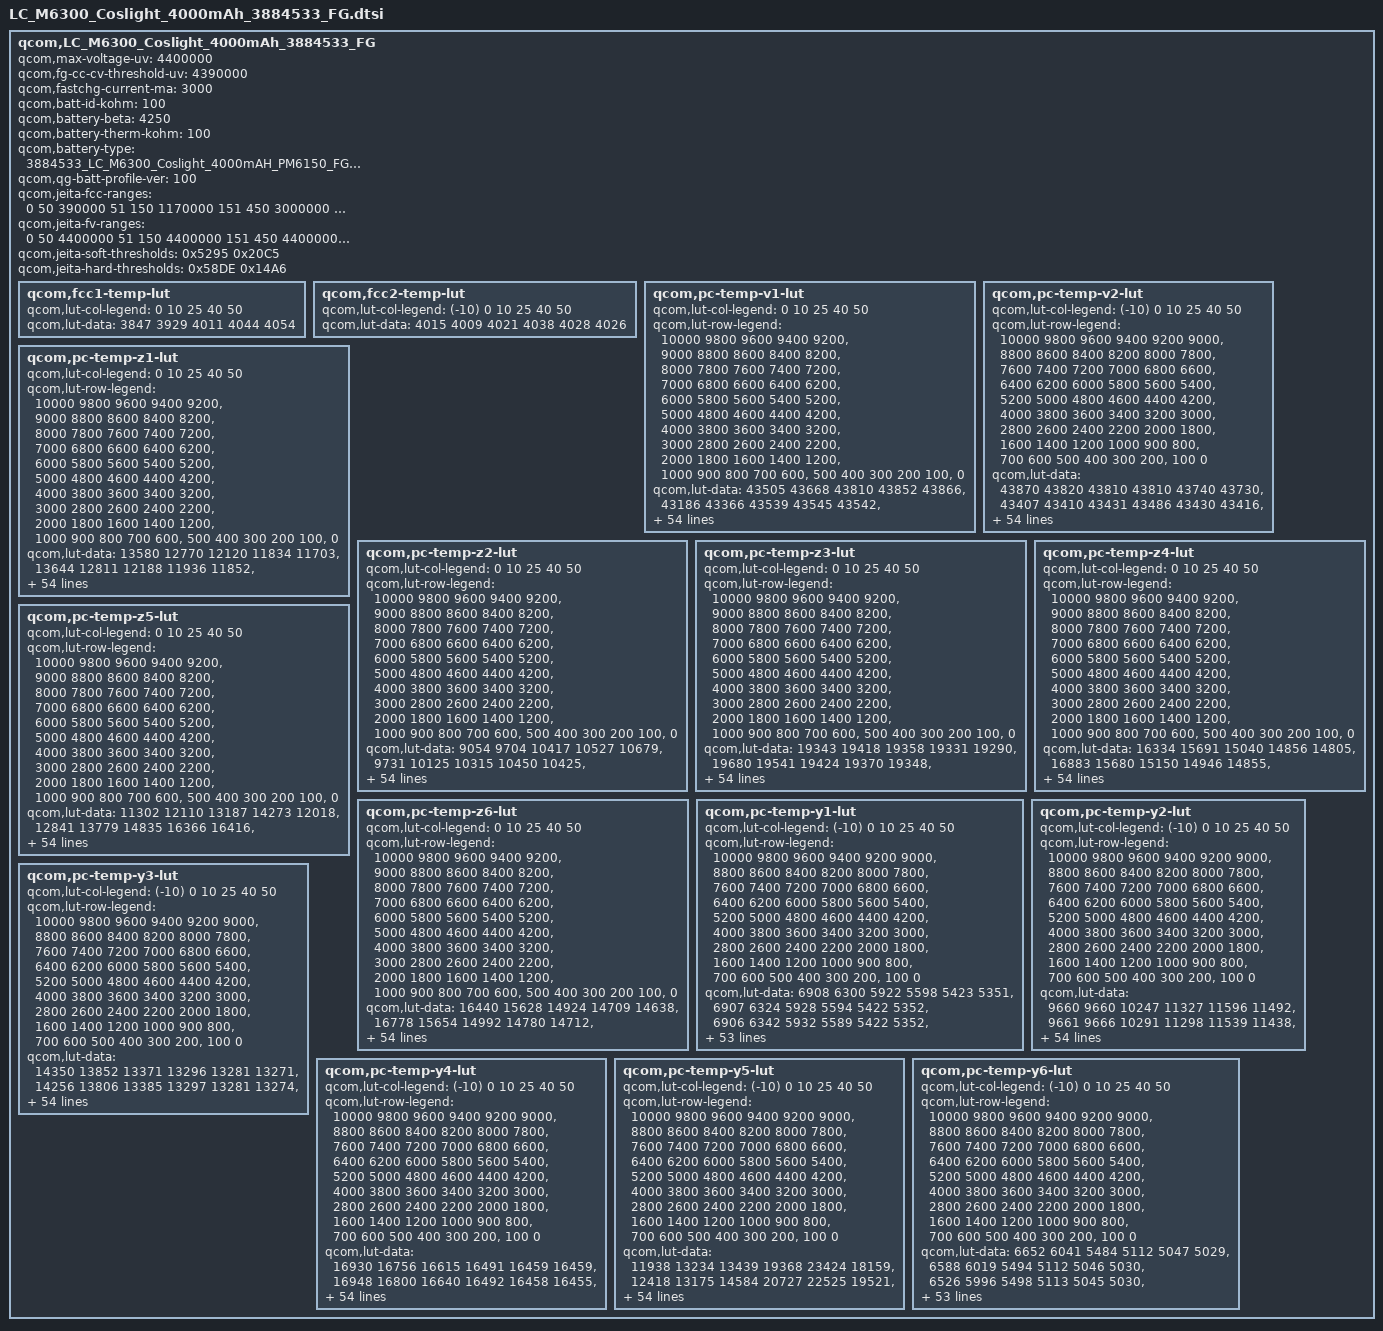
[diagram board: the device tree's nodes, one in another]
qcom,LC_M6300_Coslight_4000mAh_3884533_FG {
    /* 3884533_LC_M6300_Coslight_4000mAH_PM6150_FG_averaged_MasterSlave_Feb20th2019 */
    qcom,max-voltage-uv = <4400000>;
    qcom,fg-cc-cv-threshold-uv = <4390000>;
    qcom,fastchg-current-ma = <3000>;
    qcom,batt-id-kohm = <100>;
    qcom,battery-beta = <4250>;
    qcom,battery-therm-kohm = <100>;
    qcom,battery-type = "3884533_LC_M6300_Coslight_4000mAH_PM6150_FG_averaged_MasterSlave_Feb20th2019";
    qcom,qg-batt-profile-ver = <100>;

	qcom,jeita-fcc-ranges = <0   50  390000
				51  150   1170000
				151 450  3000000
				451 600  1950000>;
	qcom,jeita-fv-ranges = <0   50  4400000
				51  150  4400000
				151 450  4400000
				451 600  4100000>;

	/* COOL = 5 DegC, WARM = 45 DegC */
	qcom,jeita-soft-thresholds = <0x5295 0x20C5>;
	/* COLD = 0 DegC, HOT = 60 DegC */
	qcom,jeita-hard-thresholds = <0x58DE 0x14A6>;

	qcom,fcc1-temp-lut {
		qcom,lut-col-legend = <0 10 25 40 50>;
		qcom,lut-data = <3847 3929 4011 4044 4054>;
	};

	qcom,fcc2-temp-lut {
		qcom,lut-col-legend = <(-10) 0 10 25 40 50>;
		qcom,lut-data = <4015 4009 4021 4038 4028 4026>;
	};

	qcom,pc-temp-v1-lut {
		qcom,lut-col-legend = <0 10 25 40 50>;
		qcom,lut-row-legend = <10000 9800 9600 9400 9200>,
			<9000 8800 8600 8400 8200>,
			<8000 7800 7600 7400 7200>,
			<7000 6800 6600 6400 6200>,
			<6000 5800 5600 5400 5200>,
			<5000 4800 4600 4400 4200>,
			<4000 3800 3600 3400 3200>,
			<3000 2800 2600 2400 2200>,
			<2000 1800 1600 1400 1200>,
			<1000 900 800 700 600>,
			<500 400 300 200 100>,
			<0>;
		qcom,lut-data = <43505 43668 43810 43852 43866>,
			<43186 43366 43539 43545 43542>,
			<42923 43092 43258 43278 43275>,
			<42683 42843 42995 43025 43026>,
			<42451 42607 42750 42780 42783>,
			<42232 42373 42512 42543 42551>,
			<42017 42145 42278 42309 42318>,
			<41803 41925 42047 42076 42083>,
			<41596 41709 41822 41847 41852>,
			<41408 41502 41598 41621 41627>,
			<41243 41317 41383 41399 41406>,
			<41057 41149 41188 41182 41188>,
			<40796 40953 41002 40970 40972>,
			<40502 40682 40789 40763 40764>,
			<40266 40398 40528 40556 40564>,
			<40080 40183 40287 40356 40372>,
			<39917 40004 40114 40174 40188>,
			<39770 39852 39969 40007 40010>,
			<39639 39728 39829 39846 39841>,
			<39515 39617 39700 39698 39689>,
			<39400 39493 39557 39545 39537>,
			<39289 39362 39360 39350 39350>,
			<39174 39215 39132 39117 39125>,
			<39056 39016 38941 38921 38927>,
			<38943 38799 38776 38769 38770>,
			<38837 38647 38644 38640 38636>,
			<38737 38535 38557 38531 38523>,
			<38641 38448 38490 38436 38426>,
			<38548 38384 38423 38351 38338>,
			<38465 38333 38355 38274 38254>,
			<38397 38291 38293 38205 38180>,
			<38336 38256 38237 38144 38115>,
			<38296 38224 38186 38092 38057>,
			<38275 38194 38140 38044 38004>,
			<38259 38167 38102 38006 37958>,
			<38230 38137 38063 37966 37911>,
			<38188 38107 38025 37919 37857>,
			<38140 38071 37985 37865 37796>,
			<38083 38016 37927 37799 37724>,
			<38015 37935 37840 37717 37638>,
			<37928 37843 37738 37621 37539>,
			<37808 37739 37628 37512 37429>,
			<37672 37614 37499 37383 37302>,
			<37518 37450 37336 37222 37139>,
			<37361 37296 37188 37077 37004>,
			<37252 37187 37083 36987 36922>,
			<37213 37152 37060 36960 36894>,
			<37182 37128 37039 36941 36880>,
			<37153 37101 37018 36925 36859>,
			<37102 37056 36980 36868 36785>,
			<36896 36824 36766 36587 36479>,
			<36450 36379 36346 36142 36032>,
			<35872 35798 35788 35559 35445>,
			<35083 35005 35031 34759 34640>,
			<33827 33748 33870 33495 33375>,
			<30000 30000 30000 30000 30000>;
	};

	qcom,pc-temp-v2-lut {
		qcom,lut-col-legend = <(-10) 0 10 25 40 50>;
		qcom,lut-row-legend = <10000 9800 9600 9400 9200 9000>,
			<8800 8600 8400 8200 8000 7800>,
			<7600 7400 7200 7000 6800 6600>,
			<6400 6200 6000 5800 5600 5400>,
			<5200 5000 4800 4600 4400 4200>,
			<4000 3800 3600 3400 3200 3000>,
			<2800 2600 2400 2200 2000 1800>,
			<1600 1400 1200 1000 900 800>,
			<700 600 500 400 300 200>,
			<100 0>;
		qcom,lut-data = <43870 43820 43810 43810 43740 43730>,
			<43407 43410 43431 43486 43430 43416>,
			<42997 43040 43089 43187 43141 43125>,
			<42652 42719 42791 42917 42876 42861>,
			<42358 42438 42532 42674 42634 42621>,
			<42087 42178 42284 42437 42399 42386>,
			<41813 41927 42037 42200 42164 42149>,
			<41563 41691 41794 41965 41933 41915>,
			<41378 41470 41544 41737 41705 41688>,
			<41242 41255 41281 41513 41481 41467>,
			<41095 41086 41070 41293 41260 41249>,
			<40919 40991 40943 41081 41044 41032>,
			<40712 40904 40827 40871 40830 40819>,
			<40409 40682 40602 40660 40624 40615>,
			<39952 40166 40214 40446 40420 40416>,
			<39588 39750 39928 40241 40227 40225>,
			<39389 39571 39811 40042 40049 40042>,
			<39230 39435 39717 39857 39880 39866>,
			<39059 39270 39559 39703 39717 39703>,
			<38883 39087 39329 39572 39563 39553>,
			<38727 38909 39105 39412 39391 39384>,
			<38594 38738 38906 39175 39172 39168>,
			<38477 38578 38721 38929 38949 38946>,
			<38380 38447 38559 38748 38767 38764>,
			<38299 38334 38413 38596 38606 38605>,
			<38225 38243 38291 38465 38471 38470>,
			<38158 38172 38188 38351 38362 38360>,
			<38096 38111 38102 38251 38267 38263>,
			<38038 38057 38038 38164 38178 38174>,
			<37985 38009 37987 38086 38096 38091>,
			<37933 37964 37943 38015 38024 38018>,
			<37880 37922 37903 37948 37961 37954>,
			<37826 37880 37866 37887 37902 37894>,
			<37771 37836 37827 37833 37840 37832>,
			<37714 37790 37788 37783 37779 37772>,
			<37655 37742 37746 37732 37709 37697>,
			<37591 37691 37703 37679 37625 37587>,
			<37524 37636 37654 37621 37537 37473>,
			<37457 37572 37593 37553 37458 37386>,
			<37391 37500 37521 37476 37383 37309>,
			<37323 37417 37437 37390 37301 37228>,
			<37252 37314 37335 37290 37211 37140>,
			<37181 37203 37219 37173 37105 37036>,
			<37112 37088 37085 37037 36973 36902>,
			<37023 36998 36955 36912 36846 36785>,
			<36925 36918 36849 36860 36808 36748>,
			<36860 36870 36813 36840 36792 36738>,
			<36788 36834 36777 36819 36775 36722>,
			<36693 36776 36732 36776 36742 36685>,
			<36567 36682 36648 36627 36618 36534>,
			<36316 36474 36413 36240 36272 36170>,
			<35924 36027 35959 35696 35752 35644>,
			<35351 35404 35318 34962 35075 34957>,
			<34490 34520 34428 33909 34120 33980>,
			<32997 33116 33040 32142 32709 32601>,
			<28512 27870 27746 30731 27795 27712>;
	};

	qcom,pc-temp-z1-lut {
		qcom,lut-col-legend = <0 10 25 40 50>;
		qcom,lut-row-legend = <10000 9800 9600 9400 9200>,
			<9000 8800 8600 8400 8200>,
			<8000 7800 7600 7400 7200>,
			<7000 6800 6600 6400 6200>,
			<6000 5800 5600 5400 5200>,
			<5000 4800 4600 4400 4200>,
			<4000 3800 3600 3400 3200>,
			<3000 2800 2600 2400 2200>,
			<2000 1800 1600 1400 1200>,
			<1000 900 800 700 600>,
			<500 400 300 200 100>,
			<0>;
		qcom,lut-data = <13580 12770 12120 11834 11703>,
			<13644 12811 12188 11936 11852>,
			<13718 12833 12238 11960 11867>,
			<13767 12843 12249 11968 11872>,
			<13757 12851 12239 11968 11872>,
			<13721 12865 12231 11968 11871>,
			<13705 12882 12234 11968 11870>,
			<13717 12892 12243 11965 11873>,
			<13733 12899 12244 11962 11874>,
			<13727 12903 12236 11960 11874>,
			<13688 12901 12229 11959 11874>,
			<13658 12894 12231 11959 11874>,
			<13652 12884 12236 11960 11874>,
			<13649 12862 12236 11961 11874>,
			<13642 12840 12226 11959 11875>,
			<13626 12838 12218 11957 11875>,
			<13603 12839 12219 11957 11876>,
			<13566 12842 12222 11958 11878>,
			<13515 12850 12226 11959 11880>,
			<13494 12862 12232 11962 11882>,
			<13524 12872 12238 11965 11883>,
			<13566 12883 12242 11967 11885>,
			<13590 12888 12244 11968 11887>,
			<13609 12885 12248 11970 11889>,
			<13617 12882 12252 11972 11891>,
			<13615 12881 12254 11974 11893>,
			<13610 12886 12253 11977 11895>,
			<13610 12892 12250 11981 11899>,
			<13613 12900 12251 11984 11903>,
			<13618 12909 12261 11988 11907>,
			<13622 12912 12270 11991 11910>,
			<13625 12910 12271 11994 11912>,
			<13629 12907 12271 11997 11914>,
			<13637 12918 12273 12001 11916>,
			<13647 12944 12279 12004 11921>,
			<13654 12954 12285 12008 11925>,
			<13659 12949 12287 12011 11927>,
			<13665 12944 12289 12014 11928>,
			<13674 12951 12294 12017 11930>,
			<13684 12972 12308 12020 11934>,
			<13691 12981 12318 12024 11938>,
			<13695 12970 12320 12029 11942>,
			<13705 12963 12321 12034 11945>,
			<13735 12993 12316 12038 11946>,
			<13714 12987 12319 12040 11948>,
			<13708 13005 12334 12047 11952>,
			<13719 13017 12337 12045 11952>,
			<13699 13008 12338 12046 11955>,
			<13698 12985 12339 12049 11956>,
			<13699 13005 12354 12053 11960>,
			<13712 13018 12360 12057 11965>,
			<13735 13031 12366 12066 11977>,
			<13748 13053 12384 12074 11985>,
			<13780 13092 12418 12096 12000>,
			<13780 13092 12418 12096 12000>,
			<13780 13092 12418 12096 12000>;
	};

	qcom,pc-temp-z2-lut {
		qcom,lut-col-legend = <0 10 25 40 50>;
		qcom,lut-row-legend = <10000 9800 9600 9400 9200>,
			<9000 8800 8600 8400 8200>,
			<8000 7800 7600 7400 7200>,
			<7000 6800 6600 6400 6200>,
			<6000 5800 5600 5400 5200>,
			<5000 4800 4600 4400 4200>,
			<4000 3800 3600 3400 3200>,
			<3000 2800 2600 2400 2200>,
			<2000 1800 1600 1400 1200>,
			<1000 900 800 700 600>,
			<500 400 300 200 100>,
			<0>;
		qcom,lut-data = <9054 9704 10417 10527 10679>,
			<9731 10125 10315 10450 10425>,
			<9990 10243 10453 10532 10527>,
			<10117 10230 10494 10575 10620>,
			<10143 10210 10459 10574 10580>,
			<10156 10190 10423 10572 10486>,
			<10159 10167 10409 10561 10466>,
			<10150 10148 10401 10517 10529>,
			<10134 10130 10393 10489 10580>,
			<10122 10119 10384 10496 10529>,
			<10112 10121 10379 10507 10432>,
			<10098 10132 10387 10512 10418>,
			<10064 10139 10409 10514 10478>,
			<10021 10141 10430 10516 10520>,
			<10017 10143 10457 10537 10517>,
			<10090 10149 10474 10561 10512>,
			<10158 10169 10470 10555 10512>,
			<10128 10194 10464 10525 10513>,
			<10039 10228 10465 10511 10516>,
			<9999 10266 10496 10528 10541>,
			<10012 10288 10527 10560 10583>,
			<10028 10303 10541 10603 10612>,
			<10031 10310 10551 10665 10634>,
			<10030 10307 10548 10688 10658>,
			<10030 10302 10508 10682 10695>,
			<10036 10301 10477 10672 10726>,
			<10051 10304 10494 10657 10687>,
			<10065 10311 10527 10634 10532>,
			<10080 10323 10535 10606 10431>,
			<10097 10342 10530 10563 10389>,
			<10117 10356 10524 10522 10365>,
			<10140 10365 10522 10499 10374>,
			<10140 10373 10520 10481 10410>,
			<9877 10382 10522 10478 10444>,
			<9558 10390 10538 10495 10471>,
			<9540 10402 10557 10523 10504>,
			<9673 10422 10567 10581 10569>,
			<9816 10444 10576 10661 10657>,
			<9936 10463 10594 10681 10681>,
			<10041 10480 10635 10660 10661>,
			<10061 10584 10661 10643 10644>,
			<10028 12731 10645 10678 10678>,
			<9998 14102 10627 10724 10728>,
			<9981 12314 10641 10706 10715>,
			<9912 12211 10676 10704 10685>,
			<9929 19436 10720 10733 10647>,
			<9892 19400 10731 10722 10629>,
			<9913 18829 10713 10684 10698>,
			<9884 21378 10743 10816 10790>,
			<9839 19356 10797 10897 10851>,
			<9783 18292 10799 10667 10506>,
			<9805 18824 10813 10550 10457>,
			<9669 16824 10759 10539 10383>,
			<9498 14856 10665 10449 10300>,
			<9498 14856 10665 10449 10300>,
			<9498 14856 10665 10449 10300>;
	};

	qcom,pc-temp-z3-lut {
		qcom,lut-col-legend = <0 10 25 40 50>;
		qcom,lut-row-legend = <10000 9800 9600 9400 9200>,
			<9000 8800 8600 8400 8200>,
			<8000 7800 7600 7400 7200>,
			<7000 6800 6600 6400 6200>,
			<6000 5800 5600 5400 5200>,
			<5000 4800 4600 4400 4200>,
			<4000 3800 3600 3400 3200>,
			<3000 2800 2600 2400 2200>,
			<2000 1800 1600 1400 1200>,
			<1000 900 800 700 600>,
			<500 400 300 200 100>,
			<0>;
		qcom,lut-data = <19343 19418 19358 19331 19290>,
			<19680 19541 19424 19370 19348>,
			<19734 19595 19450 19384 19360>,
			<19755 19615 19459 19391 19369>,
			<19740 19624 19463 19394 19370>,
			<19697 19623 19465 19396 19370>,
			<19675 19618 19464 19396 19371>,
			<19673 19612 19461 19394 19373>,
			<19672 19608 19457 19391 19375>,
			<19670 19603 19453 19386 19371>,
			<19668 19593 19449 19379 19362>,
			<19666 19575 19445 19376 19358>,
			<19692 19568 19442 19374 19356>,
			<19751 19573 19440 19372 19355>,
			<19807 19579 19440 19371 19350>,
			<19874 19575 19438 19370 19344>,
			<19920 19553 19433 19367 19342>,
			<19874 19530 19423 19361 19340>,
			<19741 19509 19415 19356 19339>,
			<19667 19492 19408 19352 19336>,
			<19650 19490 19404 19349 19334>,
			<19640 19494 19411 19352 19335>,
			<19645 19500 19423 19361 19340>,
			<19669 19516 19425 19364 19345>,
			<19686 19536 19419 19359 19346>,
			<19685 19541 19415 19353 19347>,
			<19682 19539 19415 19361 19353>,
			<19680 19537 19418 19382 19365>,
			<19678 19535 19421 19390 19370>,
			<19675 19534 19428 19389 19369>,
			<19670 19531 19433 19387 19366>,
			<19661 19526 19432 19384 19362>,
			<19640 19519 19430 19377 19356>,
			<19484 19513 19427 19371 19350>,
			<19301 19506 19422 19365 19345>,
			<19270 19500 19417 19360 19341>,
			<19267 19494 19413 19358 19339>,
			<19265 19488 19409 19356 19337>,
			<19263 19484 19406 19355 19337>,
			<19262 19481 19405 19353 19338>,
			<19262 19472 19403 19351 19339>,
			<19262 19342 19398 19349 19338>,
			<19262 19257 19394 19348 19336>,
			<19262 19258 19394 19348 19341>,
			<19262 19258 19386 19347 19339>,
			<19262 19256 19382 19340 19327>,
			<19263 19256 19369 19336 19327>,
			<19262 19256 19360 19338 19313>,
			<19263 19256 19370 19324 19310>,
			<19263 19256 19364 19318 19307>,
			<19264 19256 19360 19342 19337>,
			<19263 19256 19348 19347 19338>,
			<19265 19257 19348 19347 19340>,
			<19269 19257 19345 19348 19342>,
			<19269 19257 19345 19348 19342>,
			<19269 19257 19345 19348 19342>;
	};

	qcom,pc-temp-z4-lut {
		qcom,lut-col-legend = <0 10 25 40 50>;
		qcom,lut-row-legend = <10000 9800 9600 9400 9200>,
			<9000 8800 8600 8400 8200>,
			<8000 7800 7600 7400 7200>,
			<7000 6800 6600 6400 6200>,
			<6000 5800 5600 5400 5200>,
			<5000 4800 4600 4400 4200>,
			<4000 3800 3600 3400 3200>,
			<3000 2800 2600 2400 2200>,
			<2000 1800 1600 1400 1200>,
			<1000 900 800 700 600>,
			<500 400 300 200 100>,
			<0>;
		qcom,lut-data = <16334 15691 15040 14856 14805>,
			<16883 15680 15150 14946 14855>,
			<16579 15640 15078 14903 14837>,
			<16200 15441 15008 14854 14812>,
			<15969 15216 14934 14820 14791>,
			<15781 15100 14868 14789 14771>,
			<15627 15013 14825 14765 14750>,
			<15503 14947 14791 14744 14727>,
			<15398 14894 14764 14729 14712>,
			<15305 14852 14741 14719 14709>,
			<15222 14818 14724 14711 14707>,
			<15149 14791 14710 14704 14704>,
			<15091 14773 14700 14698 14697>,
			<15038 14762 14699 14693 14690>,
			<14956 14754 14712 14688 14687>,
			<14799 14747 14722 14684 14684>,
			<14681 14741 14710 14679 14679>,
			<14714 14735 14686 14671 14674>,
			<14819 14730 14673 14666 14668>,
			<14866 14724 14667 14662 14662>,
			<14855 14716 14664 14660 14657>,
			<14835 14704 14685 14676 14669>,
			<14809 14697 14735 14730 14722>,
			<14772 14727 14773 14765 14754>,
			<14749 14779 14807 14779 14759>,
			<14747 14799 14825 14787 14762>,
			<14745 14806 14812 14775 14754>,
			<14745 14809 14782 14735 14723>,
			<14746 14800 14757 14710 14702>,
			<14747 14777 14735 14699 14692>,
			<14746 14758 14718 14692 14685>,
			<14743 14740 14709 14688 14680>,
			<14746 14725 14702 14686 14677>,
			<14893 14712 14696 14683 14674>,
			<15071 14702 14692 14678 14672>,
			<15094 14693 14689 14674 14671>,
			<15080 14686 14685 14676 14673>,
			<15064 14681 14682 14679 14677>,
			<15049 14680 14682 14681 14679>,
			<15036 14680 14684 14683 14680>,
			<15026 14685 14686 14683 14681>,
			<15020 14815 14680 14677 14675>,
			<15012 14902 14672 14668 14666>,
			<14997 14897 14670 14669 14668>,
			<14934 14864 14664 14663 14664>,
			<14910 14843 14647 14650 14650>,
			<14906 14837 14650 14644 14641>,
			<14902 14829 14649 14628 14638>,
			<14895 14825 14629 14629 14625>,
			<14891 14820 14633 14634 14630>,
			<14896 14834 14652 14634 14631>,
			<14916 14846 14673 14635 14634>,
			<14916 14855 14677 14637 14636>,
			<14965 14868 14687 14640 14638>,
			<14965 14868 14687 14640 14638>,
			<14965 14868 14687 14640 14638>;
	};

	qcom,pc-temp-z5-lut {
		qcom,lut-col-legend = <0 10 25 40 50>;
		qcom,lut-row-legend = <10000 9800 9600 9400 9200>,
			<9000 8800 8600 8400 8200>,
			<8000 7800 7600 7400 7200>,
			<7000 6800 6600 6400 6200>,
			<6000 5800 5600 5400 5200>,
			<5000 4800 4600 4400 4200>,
			<4000 3800 3600 3400 3200>,
			<3000 2800 2600 2400 2200>,
			<2000 1800 1600 1400 1200>,
			<1000 900 800 700 600>,
			<500 400 300 200 100>,
			<0>;
		qcom,lut-data = <11302 12110 13187 14273 12018>,
			<12841 13779 14835 16366 16416>,
			<13486 14921 16413 17675 17888>,
			<13811 15677 17659 18677 18979>,
			<13872 16295 18621 19459 19303>,
			<13894 16871 19463 20096 19481>,
			<13939 17386 20211 20700 20016>,
			<14134 17971 20903 21315 21984>,
			<14398 18779 21810 21698 23448>,
			<14565 19475 23099 21808 22885>,
			<14665 19730 24496 21887 21788>,
			<14831 19846 25876 22159 21667>,
			<15701 20155 27242 22945 22592>,
			<17731 23782 28290 23853 23243>,
			<21478 28052 29226 24980 22958>,
			<32639 27872 29730 25929 22491>,
			<41942 24752 29331 26011 22606>,
			<37197 22138 28518 25929 23824>,
			<23111 20711 28372 25902 25224>,
			<16775 19740 29248 26424 26704>,
			<16828 19919 30879 27431 27952>,
			<16958 22090 37541 29095 28076>,
			<17999 25693 48088 31715 27821>,
			<22314 37562 49381 32456 27318>,
			<26607 53671 38233 26125 23446>,
			<29073 56610 28463 19411 18917>,
			<31167 50664 26418 19852 18923>,
			<33601 44869 25241 22854 20994>,
			<36939 42770 25417 25914 23237>,
			<39191 41354 28551 29077 25535>,
			<38984 39926 32498 31912 27727>,
			<37751 38468 36046 33857 29321>,
			<35536 37094 39560 35389 30618>,
			<24747 35779 42000 36144 31640>,
			<12816 34538 43998 36555 32600>,
			<11128 33552 44959 36750 33174>,
			<11119 32647 44399 36654 32956>,
			<11116 32073 43068 36310 32198>,
			<11118 32241 41691 35479 31321>,
			<11125 32844 40143 32194 30157>,
			<11142 32701 38231 29124 29030>,
			<11196 19958 34818 28056 28136>,
			<11233 11459 32276 27329 27568>,
			<11247 11480 32658 26505 29470>,
			<11524 11607 30979 27187 28643>,
			<11525 11624 32920 25242 23207>,
			<11510 11587 24983 24677 24378>,
			<11491 11520 22433 29540 20297>,
			<11501 11520 28916 22936 22200>,
			<11524 11548 26155 19710 19397>,
			<11565 11600 20988 25381 30285>,
			<11518 11530 16956 25366 27268>,
			<11494 11466 16440 23887 25915>,
			<11324 11360 15426 22606 23439>,
			<11324 11360 15426 22606 23439>,
			<11324 11360 15426 22606 23439>;
	};

	qcom,pc-temp-z6-lut {
		qcom,lut-col-legend = <0 10 25 40 50>;
		qcom,lut-row-legend = <10000 9800 9600 9400 9200>,
			<9000 8800 8600 8400 8200>,
			<8000 7800 7600 7400 7200>,
			<7000 6800 6600 6400 6200>,
			<6000 5800 5600 5400 5200>,
			<5000 4800 4600 4400 4200>,
			<4000 3800 3600 3400 3200>,
			<3000 2800 2600 2400 2200>,
			<2000 1800 1600 1400 1200>,
			<1000 900 800 700 600>,
			<500 400 300 200 100>,
			<0>;
		qcom,lut-data = <16440 15628 14924 14709 14638>,
			<16778 15654 14992 14780 14712>,
			<16622 15647 14978 14771 14710>,
			<16419 15547 14959 14758 14707>,
			<16270 15423 14925 14746 14701>,
			<16135 15353 14889 14733 14692>,
			<16027 15297 14865 14721 14684>,
			<15945 15252 14845 14711 14677>,
			<15878 15215 14829 14702 14670>,
			<15817 15184 14814 14694 14665>,
			<15762 15155 14803 14687 14659>,
			<15718 15128 14795 14682 14655>,
			<15688 15107 14788 14678 14652>,
			<15665 15093 14787 14674 14648>,
			<15633 15081 14787 14671 14644>,
			<15590 15068 14787 14669 14640>,
			<15548 15054 14779 14664 14636>,
			<15520 15042 14764 14658 14633>,
			<15498 15033 14756 14654 14630>,
			<15480 15025 14752 14650 14627>,
			<15462 15025 14750 14648 14623>,
			<15448 15026 14763 14657 14629>,
			<15446 15028 14792 14685 14654>,
			<15447 15049 14811 14701 14671>,
			<15447 15085 14823 14706 14676>,
			<15449 15098 14830 14708 14679>,
			<15451 15102 14825 14707 14677>,
			<15453 15104 14816 14702 14672>,
			<15455 15101 14809 14697 14667>,
			<15456 15092 14804 14693 14662>,
			<15455 15085 14800 14689 14658>,
			<15450 15077 14797 14685 14654>,
			<15444 15069 14794 14682 14650>,
			<15432 15063 14791 14677 14647>,
			<15421 15058 14788 14672 14643>,
			<15417 15055 14786 14669 14640>,
			<15416 15053 14784 14669 14640>,
			<15415 15051 14783 14670 14641>,
			<15415 15053 14783 14670 14642>,
			<15416 15057 14786 14671 14643>,
			<15418 15059 14788 14671 14644>,
			<15422 15058 14786 14668 14642>,
			<15426 15057 14783 14665 14638>,
			<15428 15061 14785 14666 14641>,
			<15416 15057 14782 14664 14639>,
			<15408 15053 14776 14656 14628>,
			<15406 15050 14771 14651 14624>,
			<15405 15048 14768 14646 14616>,
			<15405 15048 14766 14639 14609>,
			<15409 15051 14767 14640 14609>,
			<15420 15064 14777 14654 14627>,
			<15439 15077 14785 14659 14632>,
			<15457 15092 14792 14663 14636>,
			<15503 15116 14803 14670 14641>,
			<15503 15116 14803 14670 14641>,
			<15503 15116 14803 14670 14641>;
	};

	qcom,pc-temp-y1-lut {
		qcom,lut-col-legend = <(-10) 0 10 25 40 50>;
		qcom,lut-row-legend = <10000 9800 9600 9400 9200 9000>,
			<8800 8600 8400 8200 8000 7800>,
			<7600 7400 7200 7000 6800 6600>,
			<6400 6200 6000 5800 5600 5400>,
			<5200 5000 4800 4600 4400 4200>,
			<4000 3800 3600 3400 3200 3000>,
			<2800 2600 2400 2200 2000 1800>,
			<1600 1400 1200 1000 900 800>,
			<700 600 500 400 300 200>,
			<100 0>;
		qcom,lut-data = <6908 6300 5922 5598 5423 5351>,
			<6907 6324 5928 5594 5422 5352>,
			<6906 6342 5932 5589 5422 5352>,
			<6906 6354 5935 5585 5421 5352>,
			<6906 6361 5936 5582 5420 5351>,
			<6906 6363 5936 5579 5418 5351>,
			<6911 6357 5935 5578 5416 5349>,
			<6920 6348 5932 5578 5414 5348>,
			<6919 6347 5933 5575 5412 5349>,
			<6907 6353 5940 5566 5411 5356>,
			<6900 6358 5944 5562 5409 5360>,
			<6915 6360 5941 5565 5404 5352>,
			<6937 6362 5937 5569 5398 5342>,
			<6935 6366 5938 5568 5398 5341>,
			<6910 6376 5947 5563 5397 5343>,
			<6896 6382 5953 5560 5397 5345>,
			<6915 6374 5950 5567 5399 5343>,
			<6945 6364 5946 5575 5402 5342>,
			<6957 6362 5945 5575 5402 5342>,
			<6963 6364 5946 5572 5402 5343>,
			<6965 6366 5947 5570 5402 5344>,
			<6937 6374 5949 5569 5402 5345>,
			<6901 6383 5950 5569 5403 5345>,
			<6899 6382 5950 5571 5403 5346>,
			<6913 6372 5950 5579 5404 5348>,
			<6927 6365 5951 5582 5404 5349>,
			<6941 6363 5955 5582 5406 5349>,
			<6951 6363 5961 5582 5408 5350>,
			<6943 6363 5956 5583 5409 5351>,
			<6910 6365 5940 5584 5411 5354>,
			<6893 6366 5933 5584 5413 5356>,
			<6923 6364 5941 5584 5416 5359>,
			<6959 6361 5949 5583 5419 5361>,
			<6962 6360 5947 5584 5423 5363>,
			<6960 6360 5937 5586 5427 5365>,
			<6956 6360 5933 5588 5428 5366>,
			<6944 6360 5932 5590 5428 5368>,
			<6931 6360 5932 5593 5428 5370>,
			<6935 6356 5935 5595 5428 5371>,
			<6952 6341 5947 5598 5429 5371>,
			<6959 6333 5955 5598 5430 5372>,
			<6911 6353 5960 5596 5431 5373>,
			<6882 6369 5962 5595 5433 5375>,
			<6926 6369 5961 5595 5439 5377>,
			<6949 6376 5965 5608 5446 5381>,
			<7019 6396 5977 5613 5446 5387>,
			<7013 6377 5985 5618 5449 5386>,
			<6972 6428 5989 5616 5448 5385>,
			<7044 6427 5974 5607 5452 5386>,
			<7052 6432 5978 5627 5452 5387>,
			<7063 6423 6007 5620 5455 5389>,
			<7083 6441 6022 5633 5462 5395>,
			<7100 6467 6039 5654 5473 5403>,
			<7152 6455 6067 5677 5485 5413>,
			<7152 6455 6067 5677 5485 5413>,
			<7152 6455 6067 5677 5485 5413>;
	};

	qcom,pc-temp-y2-lut {
		qcom,lut-col-legend = <(-10) 0 10 25 40 50>;
		qcom,lut-row-legend = <10000 9800 9600 9400 9200 9000>,
			<8800 8600 8400 8200 8000 7800>,
			<7600 7400 7200 7000 6800 6600>,
			<6400 6200 6000 5800 5600 5400>,
			<5200 5000 4800 4600 4400 4200>,
			<4000 3800 3600 3400 3200 3000>,
			<2800 2600 2400 2200 2000 1800>,
			<1600 1400 1200 1000 900 800>,
			<700 600 500 400 300 200>,
			<100 0>;
		qcom,lut-data = <9660 9660 10247 11327 11596 11492>,
			<9661 9666 10291 11298 11539 11438>,
			<9661 9671 10352 11267 11437 11376>,
			<9662 9676 10413 11234 11321 11316>,
			<9662 9681 10461 11201 11226 11266>,
			<9663 9686 10480 11165 11184 11235>,
			<9664 9691 10473 11124 11177 11221>,
			<9665 9696 10463 11085 11174 11210>,
			<9665 9695 10468 11065 11175 11191>,
			<9665 9689 10506 11054 11179 11159>,
			<9665 9685 10558 11040 11181 11123>,
			<9665 9689 10642 11009 11128 11071>,
			<9665 9694 10731 10981 11057 11026>,
			<9665 9693 10763 10993 11056 11034>,
			<9665 9685 10775 11055 11094 11087>,
			<9665 9680 10795 11113 11128 11115>,
			<9665 9679 10893 11149 11143 11103>,
			<9664 9678 11006 11185 11159 11087>,
			<9664 9678 11015 11243 11199 11133>,
			<9664 9676 10994 11322 11281 11308>,
			<9664 9676 10982 11351 11349 11394>,
			<9664 9675 10994 11309 11401 11368>,
			<9664 9675 11008 11264 11435 11337>,
			<9664 9675 11004 11274 11425 11347>,
			<9664 9675 10977 11315 11385 11392>,
			<9664 9674 10921 11341 11368 11412>,
			<9664 9673 10468 11349 11397 11364>,
			<9664 9672 9932 11357 11441 11310>,
			<9664 9671 9830 11379 11475 11360>,
			<9664 9670 9802 11409 11506 11523>,
			<9663 9669 9778 11419 11516 11592>,
			<9663 9668 9753 11417 11501 11560>,
			<9664 9667 9732 11414 11485 11527>,
			<9663 9666 9718 11415 11485 11537>,
			<9663 9665 9706 11416 11488 11572>,
			<9663 9664 9697 11411 11487 11583>,
			<9663 9664 9691 11356 11449 11540>,
			<9662 9663 9685 11303 11411 11475>,
			<9662 9662 9680 11293 11405 11407>,
			<9662 9662 9675 11287 11402 11334>,
			<9662 9661 9671 11267 11404 11312>,
			<9662 9661 9667 11191 11430 11322>,
			<9661 9661 9665 11131 11426 11349>,
			<9661 9660 9662 11085 11310 11435>,
			<9660 9660 9661 10928 11315 11228>,
			<9660 9660 9661 10949 11252 11137>,
			<9660 9659 9660 10897 11226 11083>,
			<9659 9659 9659 10927 11211 11136>,
			<9659 9659 9659 10935 11215 11167>,
			<9659 9658 9658 10881 11182 11107>,
			<9658 9658 9658 10774 11113 11052>,
			<9658 9658 9657 10677 11037 10971>,
			<9656 9657 9657 10540 10964 10990>,
			<9653 9656 9656 10445 10881 10783>,
			<9653 9656 9656 10445 10881 10783>,
			<9653 9656 9656 10445 10881 10783>;
	};

	qcom,pc-temp-y3-lut {
		qcom,lut-col-legend = <(-10) 0 10 25 40 50>;
		qcom,lut-row-legend = <10000 9800 9600 9400 9200 9000>,
			<8800 8600 8400 8200 8000 7800>,
			<7600 7400 7200 7000 6800 6600>,
			<6400 6200 6000 5800 5600 5400>,
			<5200 5000 4800 4600 4400 4200>,
			<4000 3800 3600 3400 3200 3000>,
			<2800 2600 2400 2200 2000 1800>,
			<1600 1400 1200 1000 900 800>,
			<700 600 500 400 300 200>,
			<100 0>;
		qcom,lut-data = <14350 13852 13371 13296 13281 13271>,
			<14256 13806 13385 13297 13281 13274>,
			<14167 13761 13394 13298 13281 13276>,
			<14084 13719 13398 13299 13281 13277>,
			<14009 13682 13400 13300 13281 13277>,
			<13942 13654 13400 13301 13281 13277>,
			<13885 13634 13396 13302 13281 13277>,
			<13834 13617 13391 13303 13282 13275>,
			<13776 13589 13391 13303 13283 13276>,
			<13707 13544 13398 13304 13284 13279>,
			<13674 13514 13402 13305 13285 13281>,
			<13685 13507 13386 13306 13285 13281>,
			<13700 13502 13362 13307 13285 13282>,
			<13696 13490 13359 13309 13285 13282>,
			<13668 13465 13361 13311 13285 13282>,
			<13646 13447 13362 13312 13285 13283>,
			<13640 13442 13362 13309 13287 13282>,
			<13636 13438 13362 13304 13290 13282>,
			<13636 13433 13360 13304 13290 13283>,
			<13638 13427 13350 13305 13289 13286>,
			<13640 13421 13340 13305 13288 13287>,
			<13641 13414 13334 13302 13286 13284>,
			<13642 13409 13328 13297 13284 13279>,
			<13646 13404 13325 13295 13282 13277>,
			<13658 13400 13323 13294 13280 13276>,
			<13672 13398 13319 13293 13279 13276>,
			<13687 13405 13295 13291 13280 13275>,
			<13703 13418 13269 13289 13280 13275>,
			<13721 13433 13267 13290 13279 13275>,
			<13742 13452 13270 13290 13278 13275>,
			<13764 13472 13274 13291 13278 13275>,
			<13788 13491 13280 13291 13278 13275>,
			<13815 13510 13289 13291 13279 13276>,
			<13844 13533 13298 13291 13279 13276>,
			<13877 13559 13309 13291 13279 13277>,
			<13913 13589 13323 13291 13279 13277>,
			<13950 13624 13339 13291 13279 13276>,
			<13990 13662 13359 13291 13278 13275>,
			<14032 13702 13383 13291 13278 13275>,
			<14077 13744 13413 13291 13278 13275>,
			<14125 13788 13449 13291 13278 13276>,
			<14178 13836 13495 13292 13279 13277>,
			<14239 13886 13554 13293 13280 13278>,
			<14313 13933 13636 13293 13280 13277>,
			<14394 14002 13731 13295 13277 13276>,
			<14408 13993 13703 13297 13282 13279>,
			<14479 14036 13774 13300 13283 13282>,
			<14564 14106 13846 13307 13287 13285>,
			<14656 14163 13919 13313 13290 13285>,
			<14759 14225 13989 13315 13289 13283>,
			<14853 14290 14047 13315 13286 13281>,
			<14984 14351 14126 13322 13287 13282>,
			<15352 14487 14239 13333 13292 13286>,
			<16371 14666 14348 13362 13298 13291>,
			<16371 14666 14348 13362 13298 13291>,
			<16371 14666 14348 13362 13298 13291>;
	};

	qcom,pc-temp-y4-lut {
		qcom,lut-col-legend = <(-10) 0 10 25 40 50>;
		qcom,lut-row-legend = <10000 9800 9600 9400 9200 9000>,
			<8800 8600 8400 8200 8000 7800>,
			<7600 7400 7200 7000 6800 6600>,
			<6400 6200 6000 5800 5600 5400>,
			<5200 5000 4800 4600 4400 4200>,
			<4000 3800 3600 3400 3200 3000>,
			<2800 2600 2400 2200 2000 1800>,
			<1600 1400 1200 1000 900 800>,
			<700 600 500 400 300 200>,
			<100 0>;
		qcom,lut-data = <16930 16756 16615 16491 16459 16459>,
			<16948 16800 16640 16492 16458 16455>,
			<16972 16846 16669 16495 16457 16452>,
			<16996 16887 16699 16497 16457 16450>,
			<17016 16917 16723 16499 16456 16449>,
			<17027 16928 16738 16500 16456 16449>,
			<17031 16919 16745 16500 16457 16450>,
			<17033 16906 16749 16500 16458 16451>,
			<17074 16918 16744 16501 16458 16452>,
			<17251 17004 16718 16505 16460 16452>,
			<17356 17102 16704 16510 16461 16452>,
			<17323 17205 16836 16514 16465 16453>,
			<17248 17294 17018 16518 16470 16456>,
			<17130 17246 17000 16528 16476 16459>,
			<16914 16954 16808 16547 16482 16463>,
			<16793 16778 16702 16565 16489 16468>,
			<16782 16784 16749 16579 16496 16476>,
			<16775 16793 16812 16594 16505 16485>,
			<16755 16787 16807 16618 16524 16498>,
			<16715 16747 16750 16652 16557 16516>,
			<16690 16704 16692 16663 16571 16523>,
			<16684 16661 16645 16604 16547 16513>,
			<16681 16625 16602 16528 16510 16496>,
			<16678 16616 16564 16496 16484 16478>,
			<16676 16613 16528 16474 16459 16457>,
			<16675 16612 16515 16467 16451 16449>,
			<16677 16613 16549 16467 16451 16450>,
			<16680 16614 16590 16466 16451 16451>,
			<16681 16613 16594 16467 16452 16453>,
			<16682 16607 16593 16471 16458 16457>,
			<16683 16603 16592 16473 16465 16462>,
			<16685 16607 16590 16475 16475 16470>,
			<16687 16615 16588 16477 16483 16478>,
			<16690 16622 16589 16479 16484 16485>,
			<16693 16631 16594 16480 16485 16492>,
			<16698 16640 16601 16480 16484 16493>,
			<16703 16647 16608 16480 16468 16470>,
			<16710 16655 16617 16479 16453 16447>,
			<16720 16664 16625 16478 16452 16446>,
			<16734 16674 16633 16476 16453 16449>,
			<16753 16678 16639 16476 16454 16453>,
			<16787 16665 16644 16483 16458 16458>,
			<16825 16654 16649 16490 16460 16459>,
			<16867 16652 16657 16494 16455 16449>,
			<16871 16656 16653 16494 16449 16438>,
			<16796 16641 16629 16495 16451 16448>,
			<16814 16662 16658 16515 16465 16467>,
			<16832 16684 16686 16536 16488 16494>,
			<16843 16720 16715 16571 16520 16523>,
			<16851 16750 16749 16584 16516 16501>,
			<16844 16750 16749 16556 16474 16461>,
			<16844 16719 16727 16574 16474 16458>,
			<16906 16711 16723 16610 16490 16467>,
			<17235 16740 16738 16691 16531 16502>,
			<17235 16740 16738 16691 16531 16502>,
			<17235 16740 16738 16691 16531 16502>;
	};

	qcom,pc-temp-y5-lut {
		qcom,lut-col-legend = <(-10) 0 10 25 40 50>;
		qcom,lut-row-legend = <10000 9800 9600 9400 9200 9000>,
			<8800 8600 8400 8200 8000 7800>,
			<7600 7400 7200 7000 6800 6600>,
			<6400 6200 6000 5800 5600 5400>,
			<5200 5000 4800 4600 4400 4200>,
			<4000 3800 3600 3400 3200 3000>,
			<2800 2600 2400 2200 2000 1800>,
			<1600 1400 1200 1000 900 800>,
			<700 600 500 400 300 200>,
			<100 0>;
		qcom,lut-data = <11938 13234 13439 19368 23424 18159>,
			<12418 13175 14584 20727 22525 19521>,
			<12899 13228 15790 21545 21602 20344>,
			<13317 13372 16873 21962 20733 20764>,
			<13613 13586 17651 22111 20000 20916>,
			<13722 13851 17940 22130 19479 20931>,
			<13618 14293 17797 21823 19124 19254>,
			<13463 14731 17466 21214 18869 16840>,
			<13484 14557 16896 20592 18748 16760>,
			<13816 13345 15773 19858 18691 18139>,
			<14435 12601 15179 19085 18589 18924>,
			<19035 15329 15436 18092 17872 18685>,
			<25085 19358 15980 17289 16778 18223>,
			<24567 19399 16637 17242 15965 17762>,
			<17964 16258 17582 17392 15222 17227>,
			<14140 14361 18705 17449 14923 16626>,
			<14271 14815 20314 16607 15249 15748>,
			<14451 15591 21870 15595 15667 15006>,
			<14450 16066 22492 16164 15665 15008>,
			<14295 16434 22808 18725 15484 15422>,
			<14061 16586 23077 21202 15470 16044>,
			<13473 16237 23306 23608 18541 17390>,
			<12853 15521 23552 25329 22329 19115>,
			<12782 14641 24133 25552 23150 20609>,
			<12825 13358 25204 25618 23465 22081>,
			<12847 12709 25590 25497 23545 22590>,
			<12809 12685 19920 23113 23284 21685>,
			<12761 12674 13090 20759 22768 20339>,
			<12807 12773 12354 21138 21687 19338>,
			<13030 13227 12368 22596 19805 18417>,
			<13252 13594 12399 23756 19101 18113>,
			<13423 13754 12703 24634 19481 18250>,
			<13582 13867 13122 25256 20124 18541>,
			<13741 13938 13350 25552 21011 19483>,
			<13905 13981 13508 25748 22179 21509>,
			<13966 14052 13718 25707 22572 22724>,
			<13869 14348 14114 24774 22570 23283>,
			<13733 14695 14470 23525 22566 23580>,
			<13678 14786 14575 22455 22247 23056>,
			<13651 14817 14632 21362 21391 21665>,
			<13594 14837 14643 20405 20827 21172>,
			<13303 14855 14536 19583 20502 21427>,
			<13147 14847 14390 18707 20526 21831>,
			<13442 13957 14221 17860 21385 22433>,
			<13725 13981 14788 17626 17791 20331>,
			<14443 14498 14861 18122 20178 19532>,
			<14433 13755 14450 17627 18389 19071>,
			<14775 14321 14388 18202 18300 18340>,
			<15456 14218 14677 18832 18346 17276>,
			<16566 14771 15144 19017 17995 17040>,
			<16285 15650 15073 19761 19552 18739>,
			<15112 14353 14633 19933 20581 19668>,
			<13667 14244 14123 19196 22186 23272>,
			<11855 14306 14136 20083 24671 25626>,
			<11855 14306 14136 20083 24671 25626>,
			<11855 14306 14136 20083 24671 25626>;
	};

	qcom,pc-temp-y6-lut {
		qcom,lut-col-legend = <(-10) 0 10 25 40 50>;
		qcom,lut-row-legend = <10000 9800 9600 9400 9200 9000>,
			<8800 8600 8400 8200 8000 7800>,
			<7600 7400 7200 7000 6800 6600>,
			<6400 6200 6000 5800 5600 5400>,
			<5200 5000 4800 4600 4400 4200>,
			<4000 3800 3600 3400 3200 3000>,
			<2800 2600 2400 2200 2000 1800>,
			<1600 1400 1200 1000 900 800>,
			<700 600 500 400 300 200>,
			<100 0>;
		qcom,lut-data = <6652 6041 5484 5112 5047 5029>,
			<6588 6019 5494 5112 5046 5030>,
			<6526 5996 5498 5113 5045 5030>,
			<6468 5974 5498 5113 5044 5030>,
			<6413 5951 5495 5113 5044 5030>,
			<6363 5929 5490 5112 5044 5030>,
			<6310 5904 5483 5112 5044 5030>,
			<6265 5882 5472 5111 5044 5030>,
			<6255 5865 5461 5111 5045 5030>,
			<6253 5851 5448 5112 5046 5033>,
			<6250 5846 5442 5112 5047 5035>,
			<6243 5862 5463 5113 5048 5035>,
			<6230 5886 5492 5114 5049 5035>,
			<6199 5870 5484 5117 5050 5036>,
			<6123 5775 5434 5124 5052 5037>,
			<6075 5717 5407 5129 5054 5039>,
			<6067 5717 5420 5131 5057 5041>,
			<6061 5718 5438 5134 5062 5044>,
			<6054 5716 5435 5139 5068 5048>,
			<6046 5705 5411 5148 5076 5055>,
			<6042 5693 5390 5151 5079 5058>,
			<6040 5681 5374 5132 5071 5053>,
			<6039 5672 5361 5107 5058 5044>,
			<6041 5671 5353 5097 5049 5037>,
			<6050 5672 5346 5091 5041 5031>,
			<6061 5673 5344 5088 5038 5028>,
			<6072 5681 5346 5087 5038 5028>,
			<6084 5694 5349 5087 5039 5028>,
			<6097 5708 5354 5087 5039 5029>,
			<6112 5723 5364 5090 5040 5030>,
			<6128 5739 5377 5092 5042 5032>,
			<6149 5758 5390 5094 5045 5035>,
			<6172 5778 5407 5095 5049 5038>,
			<6196 5801 5425 5097 5050 5040>,
			<6221 5826 5447 5099 5050 5043>,
			<6250 5854 5471 5100 5050 5043>,
			<6280 5884 5498 5101 5046 5036>,
			<6313 5917 5530 5102 5041 5029>,
			<6350 5953 5566 5103 5041 5029>,
			<6391 5990 5608 5104 5042 5030>,
			<6436 6028 5655 5107 5042 5032>,
			<6486 6063 5708 5113 5045 5035>,
			<6543 6100 5771 5119 5046 5036>,
			<6612 6141 5847 5127 5046 5032>,
			<6689 6196 5927 5135 5043 5029>,
			<6695 6191 5902 5139 5048 5035>,
			<6761 6234 5969 5151 5053 5043>,
			<6829 6293 6036 5166 5062 5052>,
			<6904 6346 6103 5185 5074 5061>,
			<6991 6404 6167 5194 5072 5053>,
			<7068 6456 6216 5195 5059 5041>,
			<7182 6504 6278 5223 5061 5041>,
			<7514 6607 6368 5266 5071 5048>,
			<8476 6769 6460 5347 5090 5063>,
			<8476 6769 6460 5347 5090 5063>,
			<8476 6769 6460 5347 5090 5063>;
	};

};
